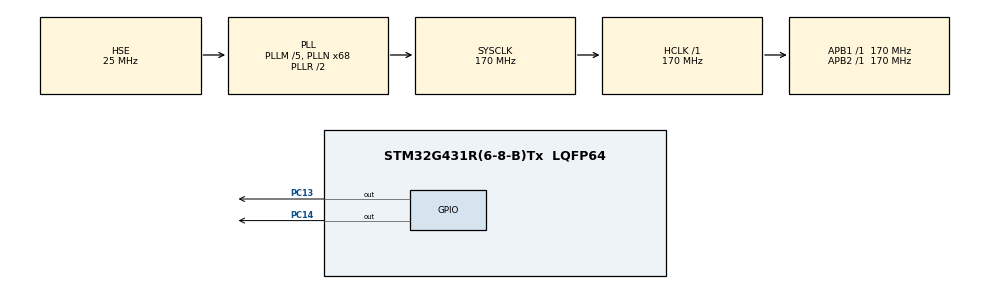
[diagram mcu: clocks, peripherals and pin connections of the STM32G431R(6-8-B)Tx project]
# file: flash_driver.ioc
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Mcu.Family=STM32G4
Mcu.Name=STM32G431R(6-8-B)Tx
Mcu.Package=LQFP64
NVIC.PriorityGroup=NVIC_PRIORITYGROUP_4
PA13.Mode=Serial_Wire
PA13.Signal=SYS_JTMS-SWDIO
PA14.Mode=Serial_Wire
PA14.Signal=SYS_JTCK-SWCLK
PC13.Signal=GPIO_Output
PC14-OSC32_IN.Signal=GPIO_Output
PF0-OSC_IN.Mode=HSE-External-Oscillator
PF0-OSC_IN.Signal=RCC_OSC_IN
PF1-OSC_OUT.Mode=HSE-External-Oscillator
PF1-OSC_OUT.Signal=RCC_OSC_OUT
ProjectManager.HeapSize=0x200
ProjectManager.StackSize=0x400
ProjectManager.TargetToolchain=MDK-ARM V5.27
RCC.ADC12Freq_Value=170000000
RCC.AHBFreq_Value=170000000
RCC.APB1Freq_Value=170000000
RCC.APB1TimFreq_Value=170000000
RCC.APB2Freq_Value=170000000
RCC.APB2TimFreq_Value=170000000
RCC.CortexFreq_Value=170000000
RCC.EXTERNAL_CLOCK_VALUE=12288000
RCC.HCLKFreq_Value=170000000
RCC.HSE_VALUE=25000000
RCC.HSI48_VALUE=48000000
RCC.HSI_VALUE=16000000
RCC.LSE_VALUE=32768
RCC.PLLM=RCC_PLLM_DIV5
RCC.PLLN=68
RCC.PLLSourceVirtual=RCC_PLLSOURCE_HSE
RCC.SYSCLKFreq_VALUE=170000000
RCC.SYSCLKSource=RCC_SYSCLKSOURCE_PLLCLK
RCC.USBFreq_Value=170000000
RCC.VCOOutputFreq_Value=340000000
VP_SYS_VS_DBSignals.Mode=DisableDeadBatterySignals
board=custom

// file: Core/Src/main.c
/* USER CODE BEGIN Header */
/**
  ******************************************************************************
  * @file           : main.c
  * @brief          : Main program body
  ******************************************************************************
  * @attention
  *
  * Copyright (c) 2023 STMicroelectronics.
  * All rights reserved.
  *
  * This software is licensed under terms that can be found in the LICENSE file
  * in the root directory of this software component.
  * If no LICENSE file comes with this software, it is provided AS-IS.
  *
  ******************************************************************************
  */
/* USER CODE END Header */
#include "main.h"
#include "gpio.h"

/* USER CODE BEGIN Includes */
#include "flash_driver.h"
/* USER CODE END Includes */

void SystemClock_Config(void);

/* USER CODE BEGIN 0 */

#define FLASH_USER_START_ADDR   ADDR_FLASH_PAGE_4   /* Start @ of user Flash area */
#define FLASH_USER_END_ADDR     (ADDR_FLASH_PAGE_63 + FLASH_PAGE_SIZE - 1)   /* End @ of user Flash area */

#define DATA_32                 ((uint32_t)0x12345678)
#define DATA_64                 ((uint64_t)0x1234567812345678)

uint64_t data_64[2] = {0x1234567812345678, 0x8765432187654321};
uint32_t data_32[3] = {0x12345678, 0x87654321, 0x87654321};

__IO uint32_t MemoryProgramStatus = 0;
__IO uint32_t data32[3] = {0};

/* USER CODE END 0 */

int main(void)
{
  /* USER CODE BEGIN 1 */
	uint32_t time1 = 0, time2 = 0;
  /* USER CODE END 1 */

  /* MCU Configuration--------------------------------------------------------*/

  /* Reset of all peripherals, Initializes the Flash interface and the Systick. */
  HAL_Init();

  /* Configure the system clock */
  SystemClock_Config();

  /* Initialize all configured peripherals */
  MX_GPIO_Init();
  /* USER CODE BEGIN 2 */

	flash_erase_pages(FLASH_USER_START_ADDR, FLASH_USER_END_ADDR);
	flash_bsp_erase_page(60);
//	flash_bsp_write(ADDR_FLASH_PAGE_63, (uint64_t *)data_64, sizeof(data_64));
//	flash_bsp_write(ADDR_FLASH_PAGE_63, (uint64_t *)data_32, sizeof(data_32));

//	flash_bsp_read_data(ADDR_FLASH_PAGE_63, (uint32_t *)data32, sizeof(data32));

  /* USER CODE END 2 */

  /* Infinite loop */
  /* USER CODE BEGIN WHILE */
  while (1)
  {
		if(HAL_GetTick() - time1 > 200)
		{
			HAL_GPIO_TogglePin(GPIOC, GPIO_PIN_13);
			time1 = HAL_GetTick();
		}

		if(HAL_GetTick() - time2 > 500)
		{
			HAL_GPIO_TogglePin(GPIOC, GPIO_PIN_14);
			time2 = HAL_GetTick();
		}
    /* USER CODE END WHILE */

  }
}

void SystemClock_Config(void)
{
  RCC_OscInitTypeDef RCC_OscInitStruct = {0};
  RCC_ClkInitTypeDef RCC_ClkInitStruct = {0};

  /** Configure the main internal regulator output voltage
  */
  HAL_PWREx_ControlVoltageScaling(PWR_REGULATOR_VOLTAGE_SCALE1_BOOST);

  /** Initializes the RCC Oscillators according to the specified parameters
  * in the RCC_OscInitTypeDef structure.
  */
  RCC_OscInitStruct.OscillatorType = RCC_OSCILLATORTYPE_HSE;
  RCC_OscInitStruct.HSEState = RCC_HSE_ON;
  RCC_OscInitStruct.PLL.PLLState = RCC_PLL_ON;
  RCC_OscInitStruct.PLL.PLLSource = RCC_PLLSOURCE_HSE;
  RCC_OscInitStruct.PLL.PLLM = RCC_PLLM_DIV5;
  RCC_OscInitStruct.PLL.PLLN = 68;
  RCC_OscInitStruct.PLL.PLLP = RCC_PLLP_DIV2;
  RCC_OscInitStruct.PLL.PLLQ = RCC_PLLQ_DIV2;
  RCC_OscInitStruct.PLL.PLLR = RCC_PLLR_DIV2;
  if (HAL_RCC_OscConfig(&RCC_OscInitStruct) != HAL_OK)
  {
    Error_Handler();
  }

  /** Initializes the CPU, AHB and APB buses clocks
  */
  RCC_ClkInitStruct.ClockType = RCC_CLOCKTYPE_HCLK|RCC_CLOCKTYPE_SYSCLK
                              |RCC_CLOCKTYPE_PCLK1|RCC_CLOCKTYPE_PCLK2;
  RCC_ClkInitStruct.SYSCLKSource = RCC_SYSCLKSOURCE_PLLCLK;
  RCC_ClkInitStruct.AHBCLKDivider = RCC_SYSCLK_DIV1;
  RCC_ClkInitStruct.APB1CLKDivider = RCC_HCLK_DIV1;
  RCC_ClkInitStruct.APB2CLKDivider = RCC_HCLK_DIV1;

  if (HAL_RCC_ClockConfig(&RCC_ClkInitStruct, FLASH_LATENCY_4) != HAL_OK)
  {
    Error_Handler();
  }
}

void Error_Handler(void)
{
  __disable_irq();
  while (1)
  {
  }
}
